# MM32F3270 register map
File version: 3.01
CPU: CM3 r2p1, selectable endian, MPU, no FPU, 3 interrupt priority bits
Registers are 32-bit, read-write, reset 0x0 unless marked. A register's access mark holds for its fields unless they carry their own. Offsets are from the block's base; [hi:lo] are bit positions; {n}, {i} and the like mark numbered series.

## IWDG — Independent watchdog
Base 0x40003000
0x00 KR wo — Key register
  [15:0] KEY — Key value
0x04 PR — Prescaler register
  [2:0] PR — Prescaler divider
0x08 RLR reset 0xFFF — Reload register
  [11:0] RL — Watchdog counter reload value
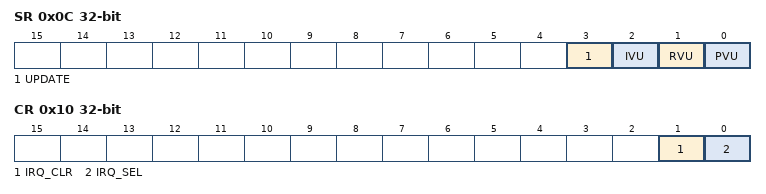
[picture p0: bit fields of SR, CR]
0x0C SR ro — Status register
  [3] UPDATE — Watchdog Reloads Update Flag
  [2] IVU — Watchdog interrupt generate value update
  [1] RVU — Watchdog counter reload value update
  [0] PVU — Watchdog prescaler value update
0x10 CR — Control register
  [1] IRQ_CLR — Interruput clear
  [0] IRQ_SEL — Interruput select
0x14 IGEN reset 0xFFF — Interruput generate value register
  [11:0] IGEN — Watchdog Interrupt Generate value
0x18 CNT ro — Counter
  [11:0] CNT — Current value of watchdog counter
0x1C PS ro reset 0x1 — prescaler Counter
  [7:0] PS — Watchdog prescaler counter value

## PWR — Power control
Base 0x40007000
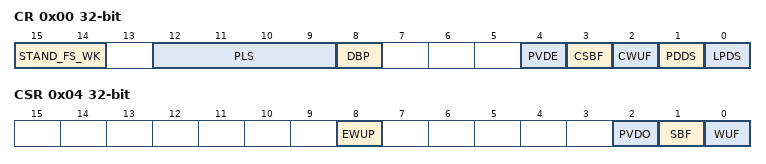
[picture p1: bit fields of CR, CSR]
0x00 CR — control register
  [15:14] STAND_FS_WK — Quickly wake up the Standby mode selection bit
  [12:9] PLS — PVD level selection
  [8] DBP — domain write protection
  [4] PVDE — Power voltage detector enable
  [3] CSBF — Clear standby flag
  [2] CWUF — Clear wakeup flag
  [1] PDDS — Power down deepsleep
  [0] LPDS — Low power deepsleep
0x04 CSR — Control Status Register
  [8] EWUP — Enable WKUP pin
  [2] PVDO — PVD output
  [1] SBF — Standby flag
  [0] WUF — Wakeup flag

## RTC — Real time clock
Base 0x40002800
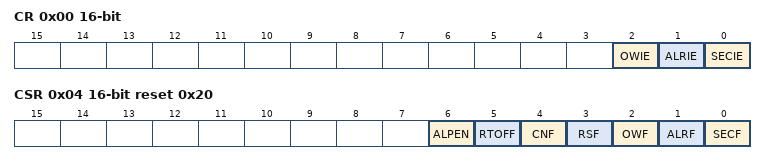
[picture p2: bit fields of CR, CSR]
0x00 CR 16-bit — configuration register
  [2] OWIE — Overflow interrupt enable
  [1] ALRIE — Alarm interrupt enable
  [0] SECIE — HSI delay time
0x04 CSR 16-bit reset 0x20
  [6] ALPEN — RTC alarm loop enable
  [5] RTOFF ro — RTC operation OFF
  [4] CNF — Configuration flag
  [3] RSF write-0-clears — Registers synchronized flag
  [2] OWF write-0-clears — Overflow flag
  [1] ALRF write-0-clears — Alarm flag
  [0] SECF write-0-clears — Second flag
0x08 PRLH 16-bit wo — Prescaler load high register
  [3:0] RTC_PRL — RTC prescaler reload value high
0x0C PRLL 16-bit wo — Prescaler load low register
  [15:0] RTC_PRL — RTC prescaler reload value low
0x10 DIVH 16-bit ro — Prescaler divider factor high register
  [3:0] RTC_DIV — RTC clock divider high
0x14 DIVL 16-bit ro — Prescaler divider factor low register
  [15:0] RTC_DIV — RTC clock divider low
0x18 CNTH 16-bit — Counter high register
  [15:0] RTC_CNT — RTC counter high
0x1C CNTL — Counter low register
  [15:0] RTC_CNT — RTC counter low
0x20 ALRH 16-bit reset 0xFFFF — Alarm high register
  [15:0] RTC_ALR — RTC alarm high
0x24 ALRL reset 0xFFFF — Alarm low register
  [15:0] RTC_ALR — RTC alarm low
0x28 RTC_MSRH 16-bit — RTC millisecond alarm high register
  [3:0] MSR — RTC msec high
0x2C RTC_MSRL 16-bit — RTC millisecond alarm low register
  [15:0] MSR — RTC msec low

## SYSCFG
Base 0x40010000
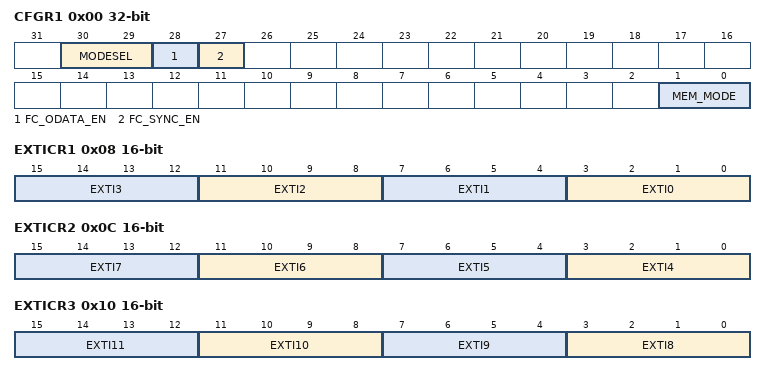
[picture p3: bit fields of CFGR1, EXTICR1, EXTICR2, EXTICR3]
0x00 CFGR1 — SYSCFG configuration register 1
  [30:29] MODESEL — FSMC mode selection
  [28] FC_ODATA_EN — FSMC address data multiplexing pin can only be used as data
  [27] FC_SYNC_EN — FSMC synchronization enable
  [1:0] MEM_MODE — Memory selection bit is set and cleared by software
0x08 EXTICR1 16-bit — External interrupt configuration register 1
  [4n+3:4n] EXTI{n} (n=0..3) — EXTI {n} configuration
0x0C EXTICR2 16-bit — External interrupt configuration register 2
  [4n-13:4n-16] EXTI{n} (n=4..7) — EXTI {n} configuration
0x10 EXTICR3 16-bit — External interrupt configuration register 3
  [4n-29:4n-32] EXTI{n} (n=8..11) — EXTI {n} configuration
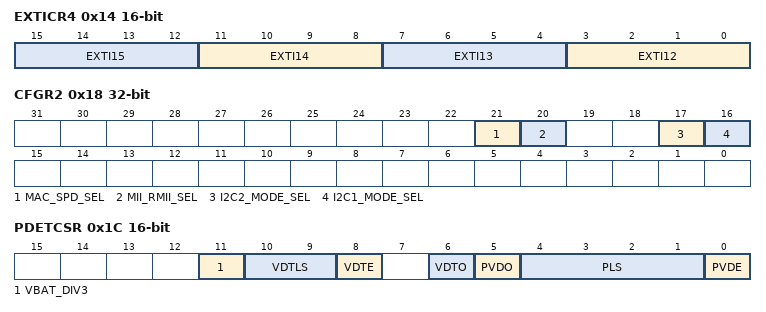
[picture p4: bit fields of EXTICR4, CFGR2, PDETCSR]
0x14 EXTICR4 16-bit — External interrupt configuration register 4
  [4n-45:4n-48] EXTI{n} (n=12..15) — EXTI {n} configuration
0x18 CFGR2 — SYSCFG configuration register 1
  [21] MAC_SPD_SEL — MAC simplifies media independent interface speed selection
  [20] MII_RMII_SEL — Ethernet PHY interface selection
  [17] I2C2_MODE_SEL — I2C2 port mode selection bit
  [16] I2C1_MODE_SEL — I2C1 port mode selection bit
0x1C PDETCSR 16-bit — Power detection configuration status register
  [11] VBAT_DIV3 — ADC detection VBat_DIV3 partial pressure value enable
  [10:9] VDTLS — VDT detection threshold selection
  [8] VDTE — VDT enable
  [6] VDTO — VDT output status
  [5] PVDO — PVD output status
  [4:1] PLS — PVD threshold selection
  [0] PVDE — PVD enable
